AUTOSAR XML (schema 00044)
package /ComponentTypes
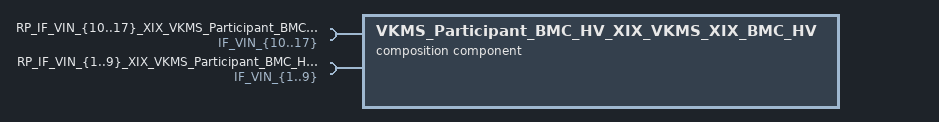
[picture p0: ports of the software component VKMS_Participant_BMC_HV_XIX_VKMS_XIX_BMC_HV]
  composition sw component type VKMS_Participant_BMC_HV_XIX_VKMS_XIX_BMC_HV
    17 x require port:
      RP_IF_VIN_{10..17}_XIX_VKMS_Participant_BMC_HV_XIX_VKMS_XIX_BMC_HV: nonqueued-receiver-com-spec=DE_VIN_{10..17}, required-interface=IF_VIN_{10..17}
      RP_IF_VIN_{1..9}_XIX_VKMS_Participant_BMC_HV_XIX_VKMS_XIX_BMC_HV: nonqueued-receiver-com-spec=DE_VIN_{1..9}, required-interface=IF_VIN_{1..9}
